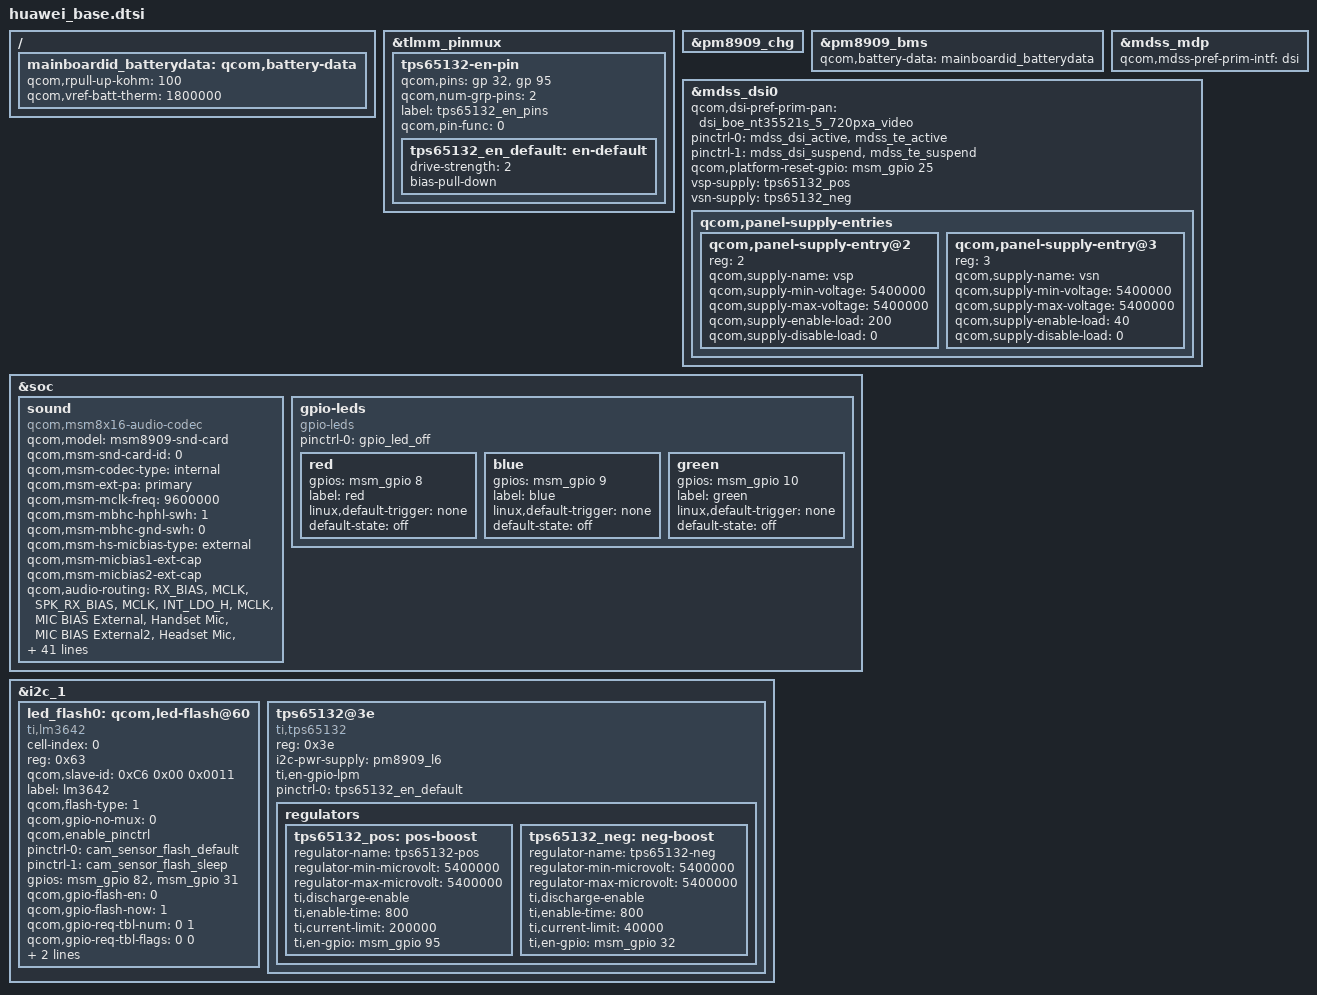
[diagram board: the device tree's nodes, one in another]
/*=============================================================================

                              Huawei Base Dtsi File

GENERAL DESCRIPTION
  This file is for include the Communal node

Copyright 2010-2014 by HUAWEI Technologies, Inc.  All Rights Reserved.
=============================================================================*/
#include "boe-nt35521s-5-720p-video.dtsi"
&tlmm_pinmux {

	tps65132-en-pin {
		qcom,pins = <&gp 32>, <&gp 95>;
		qcom,num-grp-pins = <2>;
		label = "tps65132_en_pins";
		qcom,pin-func = <0>;

		tps65132_en_default: en-default {
			drive-strength = <2>;
			bias-pull-down;
		};
	};

};

&pm8909_chg {
	status = "ok";
};

/ {
	mainboardid_batterydata: qcom,battery-data {
		qcom,rpull-up-kohm = <100>;
		qcom,vref-batt-therm = <1800000>;

		#include "batterydata-palladium.dtsi"
	};
};

&pm8909_bms {
	status = "ok";
	qcom,battery-data = <&mainboardid_batterydata>;
};

&mdss_mdp {
	qcom,mdss-pref-prim-intf = "dsi";
};

&mdss_dsi0 {
	qcom,dsi-pref-prim-pan = <&dsi_boe_nt35521s_5_720pxa_video>;
	pinctrl-names = "mdss_default", "mdss_sleep";
	pinctrl-0 = <&mdss_dsi_active &mdss_te_active>;
	pinctrl-1 = <&mdss_dsi_suspend &mdss_te_suspend>;

	qcom,platform-reset-gpio = <&msm_gpio 25 0>;
        vsp-supply = <&tps65132_pos>;
        vsn-supply = <&tps65132_neg>;
        qcom,panel-supply-entries {
                #address-cells = <1>;
                #size-cells = <0>;

                qcom,panel-supply-entry@2 {
                        reg = <2>;
                        qcom,supply-name = "vsp";
                        qcom,supply-min-voltage = <5400000>;
                        qcom,supply-max-voltage = <5400000>;
                        qcom,supply-enable-load = <200>;
                        qcom,supply-disable-load = <0>;
                };

                qcom,panel-supply-entry@3 {
                        reg = <3>;
                        qcom,supply-name = "vsn";
                        qcom,supply-min-voltage = <5400000>;
                        qcom,supply-max-voltage = <5400000>;
                        qcom,supply-enable-load = <40>;
                        qcom,supply-disable-load = <0>;
                };
        };
};

&soc {
	sound {
		compatible = "qcom,msm8x16-audio-codec";
		qcom,model = "msm8909-snd-card";
		qcom,msm-snd-card-id = <0>;
		qcom,msm-codec-type = "internal";
		qcom,msm-ext-pa = "primary";
		qcom,msm-mclk-freq = <9600000>;
		qcom,msm-mbhc-hphl-swh = <1>;
		qcom,msm-mbhc-gnd-swh = <0>;
		qcom,msm-hs-micbias-type = "external";
		qcom,msm-micbias1-ext-cap;
		qcom,msm-micbias2-ext-cap;
		qcom,audio-routing =
			"RX_BIAS", "MCLK",
			"SPK_RX_BIAS", "MCLK",
			"INT_LDO_H", "MCLK",
			"MIC BIAS External", "Handset Mic",
			"MIC BIAS External2", "Headset Mic",
			"MIC BIAS External", "Secondary Mic",
			"AMIC1", "MIC BIAS External",
			"AMIC2", "MIC BIAS External2",
			"AMIC3", "MIC BIAS External";
		pinctrl-names = "cdc_lines_act",
				"cdc_lines_sus",
				"cross_conn_det_act",
				"cross_conn_det_sus";
		pinctrl-0 = <&cdc_pdm_lines_act>;
		pinctrl-1 = <&cdc_pdm_lines_sus>;
		pinctrl-2 = <&cross_conn_det_act>;
		pinctrl-3 = <&cross_conn_det_sus>;
		asoc-platform = <&pcm0>, <&pcm1>, <&voip>, <&voice>,
				<&loopback>, <&compress>, <&hostless>,
				<&afe>, <&lsm>, <&routing>, <&lpa>,
				<&voice_svc>;
		asoc-platform-names = "msm-pcm-dsp.0", "msm-pcm-dsp.1",
				"msm-voip-dsp", "msm-pcm-voice", "msm-pcm-loopback",
				"msm-compress-dsp", "msm-pcm-hostless", "msm-pcm-afe",
				"msm-lsm-client", "msm-pcm-routing", "msm-pcm-lpa",
				"msm-voice-svc";
		asoc-cpu = <&dai_pri_auxpcm>, <&dai_hdmi>,
				<&dai_mi2s0>, <&dai_mi2s1>, <&dai_mi2s2>, <&dai_mi2s3>,
				<&sb_0_rx>, <&sb_0_tx>, <&sb_1_rx>, <&sb_1_tx>,
				<&sb_3_rx>, <&sb_3_tx>, <&sb_4_rx>, <&sb_4_tx>,
				<&bt_sco_rx>, <&bt_sco_tx>, <&int_fm_rx>, <&int_fm_tx>,
				<&afe_pcm_rx>, <&afe_pcm_tx>, <&afe_proxy_rx>, <&afe_proxy_tx>,
				<&incall_record_rx>, <&incall_record_tx>, <&incall_music_rx>,
				<&incall_music_2_rx>;
		asoc-cpu-names = "msm-dai-q6-auxpcm.1", "msm-dai-q6-hdmi.8",
				"msm-dai-q6-mi2s.0", "msm-dai-q6-mi2s.1",
				"msm-dai-q6-mi2s.2", "msm-dai-q6-mi2s.3",
				"msm-dai-q6-dev.16384", "msm-dai-q6-dev.16385",
				"msm-dai-q6-dev.16386", "msm-dai-q6-dev.16387",
				"msm-dai-q6-dev.16390", "msm-dai-q6-dev.16391",
				"msm-dai-q6-dev.16392", "msm-dai-q6-dev.16393",
				"msm-dai-q6-dev.12288", "msm-dai-q6-dev.12289",
				"msm-dai-q6-dev.12292", "msm-dai-q6-dev.12293",
				"msm-dai-q6-dev.224", "msm-dai-q6-dev.225",
				"msm-dai-q6-dev.241", "msm-dai-q6-dev.240",
				"msm-dai-q6-dev.32771", "msm-dai-q6-dev.32772",
				"msm-dai-q6-dev.32773", "msm-dai-q6-dev.32770";
		asoc-codec = <&stub_codec>, <&pm8909_conga_dig>;
		asoc-codec-names = "msm-stub-codec.1", "tombak_codec";
	};

	gpio-leds {
		compatible = "gpio-leds";
		status = "okay";
		pinctrl-names = "default";
		pinctrl-0 = <&gpio_led_off>;
		red {
			gpios = <&msm_gpio 8 0>;
			label = "red";
			linux,default-trigger = "none";
			default-state = "off";
		};

		blue {
			gpios = <&msm_gpio 9 0>;
			label = "blue";
			linux,default-trigger = "none";
			default-state = "off";
		};

		green {
			gpios = <&msm_gpio 10 0>;
			label = "green";
			linux,default-trigger = "none";
			default-state = "off";
		};
	};
};

&i2c_1 {
	led_flash0: qcom,led-flash@60 {
		cell-index = <0>;
		reg = <0x63>;
		qcom,slave-id = <0xC6 0x00 0x0011>;
		compatible = "ti,lm3642";
		label = "lm3642";
		qcom,flash-type = <1>;
		qcom,gpio-no-mux = <0>;
		qcom,enable_pinctrl;
		pinctrl-names = "cam_flash_default", "cam_flash_suspend";
		pinctrl-0 = <&cam_sensor_flash_default>;
		pinctrl-1 = <&cam_sensor_flash_sleep>;
		gpios = <&msm_gpio 82 0>,
			<&msm_gpio 31 0>;
		qcom,gpio-flash-en = <0>;
		qcom,gpio-flash-now = <1>;
		qcom,gpio-req-tbl-num = <0 1>;
		qcom,gpio-req-tbl-flags = <0 0>;
		qcom,gpio-req-tbl-label = "FLASH_EN",
			"FLASH_NOW";
		qcom,cci-master = <0>;
	};
	
	tps65132@3e {
		compatible = "ti,tps65132";
		reg = <0x3e>;
		i2c-pwr-supply = <&pm8909_l6>;
		ti,en-gpio-lpm;
		pinctrl-names = "default";
		pinctrl-0 = <&tps65132_en_default>;

		regulators {
			tps65132_pos: pos-boost {
				regulator-name = "tps65132-pos";
				regulator-min-microvolt = <5400000>;
				regulator-max-microvolt = <5400000>;
				ti,discharge-enable;
				ti,enable-time = <800>;
				ti,current-limit = <200000>;
				ti,en-gpio = <&msm_gpio 95 0>;
			};

			tps65132_neg: neg-boost {
				regulator-name = "tps65132-neg";
				regulator-min-microvolt = <5400000>;
				regulator-max-microvolt = <5400000>;
				ti,discharge-enable;
				ti,enable-time = <800>;
				ti,current-limit = <40000>;
				ti,en-gpio = <&msm_gpio 32 0>;
			};
		};
	};
};
